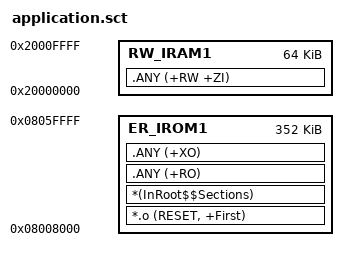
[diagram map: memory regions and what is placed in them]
; V6.0.0 keeps the established APP map. Existing BL occupies the first 32 KiB.
LR_IROM1 0x08008000 0x00058000 {
  ER_IROM1 0x08008000 0x00058000 {
    *.o (RESET, +First)
    *(InRoot$$Sections)
    .ANY (+RO)
    .ANY (+XO)
  }
  RW_IRAM1 0x20000000 0x00010000 {
    .ANY (+RW +ZI)
  }
}
